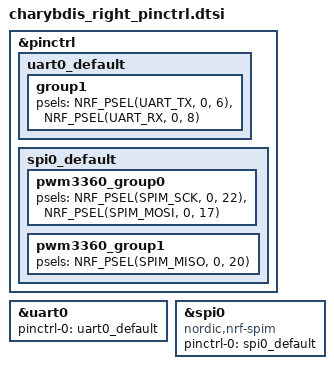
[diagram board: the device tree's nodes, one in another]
&pinctrl {
    uart0_default: uart0_default {
            group1 {
                psels = <NRF_PSEL(UART_TX, 0, 6)>, // EXT1
                        <NRF_PSEL(UART_RX, 0, 8)>; // EXT2
            };
        };


    spi0_default: spi0_default {
        pwm3360_group0{
            psels = <NRF_PSEL(SPIM_SCK, 0, 22)>,
                    <NRF_PSEL(SPIM_MOSI, 0, 17)>;
        };
        pwm3360_group1{
            psels = <NRF_PSEL(SPIM_MISO, 0, 20)>;
//           input-enable;
        };
    };

};
&uart0 {
    status = "okay";
    pinctrl-0 = <&uart0_default>;
    pinctrl-names = "default";
};
&spi0 {
    compatible ="nordic,nrf-spim"
    status = "okay";
    pinctrl-0 = <&spi0_default>;
    pinctrl-names = "default";
};
